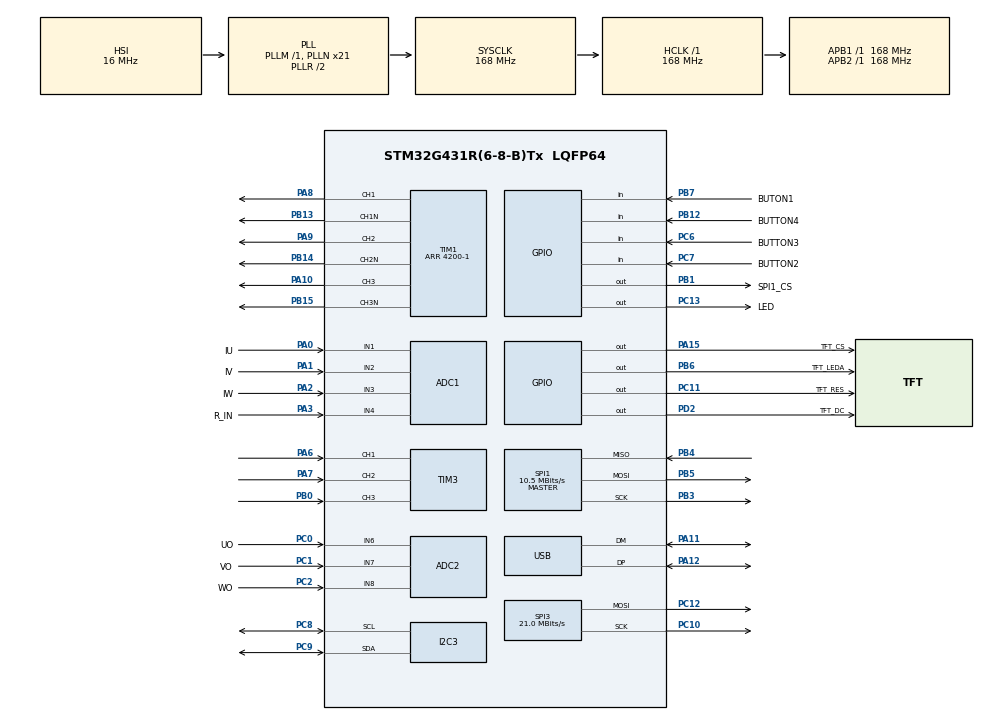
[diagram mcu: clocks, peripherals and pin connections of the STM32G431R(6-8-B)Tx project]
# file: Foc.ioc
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ADC1.Channel-0\#ChannelRegularConversion=ADC_CHANNEL_1
ADC1.ContinuousConvMode=ENABLE
ADC1.EOCSelection=ADC_EOC_SEQ_CONV
ADC1.EnableInjectedConversion=ENABLE
ADC1.EnableInjectedOversampling=DISABLE
ADC1.ExternalTrigInjecConv=ADC_EXTERNALTRIGINJEC_T1_CC4
ADC1.InjNumberOfConversion=4
ADC1.InjectedChannel-1\#ChannelInjectedConversion=ADC_CHANNEL_2
ADC1.InjectedChannel-2\#ChannelInjectedConversion=ADC_CHANNEL_3
ADC1.InjectedChannel-3\#ChannelInjectedConversion=ADC_CHANNEL_1
ADC1.InjectedChannel-4\#ChannelInjectedConversion=ADC_CHANNEL_4
ADC1.InjectedOffsetNumber-1\#ChannelInjectedConversion=ADC_OFFSET_NONE
ADC1.InjectedOffsetNumber-2\#ChannelInjectedConversion=ADC_OFFSET_NONE
ADC1.InjectedOffsetNumber-3\#ChannelInjectedConversion=ADC_OFFSET_NONE
ADC1.InjectedOffsetNumber-4\#ChannelInjectedConversion=ADC_OFFSET_NONE
ADC1.InjectedRank-1\#ChannelInjectedConversion=1
ADC1.InjectedRank-2\#ChannelInjectedConversion=2
ADC1.InjectedRank-3\#ChannelInjectedConversion=3
ADC1.InjectedRank-4\#ChannelInjectedConversion=4
ADC1.InjectedSamplingTime-1\#ChannelInjectedConversion=ADC_SAMPLETIME_2CYCLES_5
ADC1.InjectedSamplingTime-2\#ChannelInjectedConversion=ADC_SAMPLETIME_2CYCLES_5
ADC1.InjectedSamplingTime-3\#ChannelInjectedConversion=ADC_SAMPLETIME_2CYCLES_5
ADC1.InjectedSamplingTime-4\#ChannelInjectedConversion=ADC_SAMPLETIME_2CYCLES_5
ADC1.NbrOfConversionFlag=1
ADC1.OffsetNumber-0\#ChannelRegularConversion=ADC_OFFSET_NONE
ADC1.Rank-0\#ChannelRegularConversion=1
ADC1.Rank1_Channel=ADC_CHANNEL_2
ADC1.Rank2_Channel=ADC_CHANNEL_3
ADC1.Rank3_Channel=ADC_CHANNEL_1
ADC1.Rank4_Channel=ADC_CHANNEL_4
ADC1.SamplingTime-0\#ChannelRegularConversion=ADC_SAMPLETIME_2CYCLES_5
ADC1.master=1
ADC2.Channel-10\#ChannelRegularConversion=ADC_CHANNEL_6
ADC2.Channel-11\#ChannelRegularConversion=ADC_CHANNEL_7
ADC2.Channel-12\#ChannelRegularConversion=ADC_CHANNEL_8
ADC2.ContinuousConvMode=ENABLE
ADC2.EOCSelection=ADC_EOC_SEQ_CONV
ADC2.EnableRegularConversion=ENABLE
ADC2.NbrOfConversion=3
ADC2.NbrOfConversionFlag=1
ADC2.OffsetNumber-10\#ChannelRegularConversion=ADC_OFFSET_NONE
ADC2.OffsetNumber-11\#ChannelRegularConversion=ADC_OFFSET_NONE
ADC2.OffsetNumber-12\#ChannelRegularConversion=ADC_OFFSET_NONE
ADC2.Rank-10\#ChannelRegularConversion=1
ADC2.Rank-11\#ChannelRegularConversion=2
ADC2.Rank-12\#ChannelRegularConversion=3
ADC2.SamplingTime-10\#ChannelRegularConversion=ADC_SAMPLETIME_6CYCLES_5
ADC2.SamplingTime-11\#ChannelRegularConversion=ADC_SAMPLETIME_6CYCLES_5
ADC2.SamplingTime-12\#ChannelRegularConversion=ADC_SAMPLETIME_6CYCLES_5
Dma.ADC1.1.Direction=DMA_PERIPH_TO_MEMORY
Dma.ADC1.1.EventEnable=DISABLE
Dma.ADC1.1.Instance=DMA1_Channel2
Dma.ADC1.1.MemDataAlignment=DMA_MDATAALIGN_HALFWORD
Dma.ADC1.1.MemInc=DMA_MINC_ENABLE
Dma.ADC1.1.Mode=DMA_CIRCULAR
Dma.ADC1.1.PeriphDataAlignment=DMA_PDATAALIGN_HALFWORD
Dma.ADC1.1.PeriphInc=DMA_PINC_DISABLE
Dma.ADC1.1.Polarity=HAL_DMAMUX_REQ_GEN_RISING
Dma.ADC1.1.Priority=DMA_PRIORITY_LOW
Dma.ADC1.1.RequestNumber=1
Dma.ADC1.1.SignalID=NONE
Dma.ADC1.1.SyncEnable=DISABLE
Dma.ADC1.1.SyncPolarity=HAL_DMAMUX_SYNC_NO_EVENT
Dma.ADC1.1.SyncRequestNumber=1
Dma.ADC1.1.SyncSignalID=NONE
Dma.Request0=SPI3_TX
Dma.Request1=ADC1
Dma.Request2=SPI1_TX
Dma.SPI1_TX.2.Direction=DMA_MEMORY_TO_PERIPH
Dma.SPI1_TX.2.EventEnable=DISABLE
Dma.SPI1_TX.2.Instance=DMA1_Channel3
Dma.SPI1_TX.2.MemDataAlignment=DMA_MDATAALIGN_HALFWORD
Dma.SPI1_TX.2.MemInc=DMA_MINC_ENABLE
Dma.SPI1_TX.2.Mode=DMA_NORMAL
Dma.SPI1_TX.2.PeriphDataAlignment=DMA_PDATAALIGN_HALFWORD
Dma.SPI1_TX.2.PeriphInc=DMA_PINC_DISABLE
Dma.SPI1_TX.2.Polarity=HAL_DMAMUX_REQ_GEN_RISING
Dma.SPI1_TX.2.Priority=DMA_PRIORITY_LOW
Dma.SPI1_TX.2.RequestNumber=1
Dma.SPI1_TX.2.SignalID=NONE
Dma.SPI1_TX.2.SyncEnable=DISABLE
Dma.SPI1_TX.2.SyncPolarity=HAL_DMAMUX_SYNC_NO_EVENT
Dma.SPI1_TX.2.SyncRequestNumber=1
Dma.SPI1_TX.2.SyncSignalID=NONE
Dma.SPI3_TX.0.Direction=DMA_MEMORY_TO_PERIPH
Dma.SPI3_TX.0.EventEnable=DISABLE
Dma.SPI3_TX.0.Instance=DMA1_Channel1
Dma.SPI3_TX.0.MemDataAlignment=DMA_MDATAALIGN_BYTE
Dma.SPI3_TX.0.MemInc=DMA_MINC_ENABLE
Dma.SPI3_TX.0.Mode=DMA_NORMAL
Dma.SPI3_TX.0.PeriphDataAlignment=DMA_PDATAALIGN_BYTE
Dma.SPI3_TX.0.PeriphInc=DMA_PINC_DISABLE
Dma.SPI3_TX.0.Polarity=HAL_DMAMUX_REQ_GEN_RISING
Dma.SPI3_TX.0.Priority=DMA_PRIORITY_LOW
Dma.SPI3_TX.0.RequestNumber=1
Dma.SPI3_TX.0.SignalID=NONE
Dma.SPI3_TX.0.SyncEnable=DISABLE
Dma.SPI3_TX.0.SyncPolarity=HAL_DMAMUX_SYNC_NO_EVENT
Dma.SPI3_TX.0.SyncRequestNumber=1
Dma.SPI3_TX.0.SyncSignalID=NONE
I2C3.Timing=0x60505F8C
Mcu.Family=STM32G4
Mcu.Name=STM32G431R(6-8-B)Tx
Mcu.Package=LQFP64
NVIC.ADC1_2_IRQn=true\:0\:0\:false\:false\:true\:true\:true\:true
NVIC.DMA1_Channel1_IRQn=true\:0\:0\:false\:false\:true\:false\:true\:true
NVIC.DMA1_Channel2_IRQn=true\:0\:0\:false\:false\:true\:false\:true\:true
NVIC.DMA1_Channel3_IRQn=true\:0\:0\:false\:false\:true\:false\:true\:true
NVIC.PriorityGroup=NVIC_PRIORITYGROUP_4
NVIC.TIM3_IRQn=true\:1\:0\:true\:false\:true\:true\:true\:true
NVIC.TIM4_IRQn=true\:2\:0\:true\:false\:true\:true\:true\:true
NVIC.USB_LP_IRQn=true\:0\:0\:false\:false\:true\:false\:true\:true
PA0.GPIO_Label=IU
PA0.Mode=IN1-Single-Ended
PA0.Signal=ADC1_IN1
PA1.GPIO_Label=IV
PA1.Mode=IN2-Single-Ended
PA1.Signal=ADC1_IN2
PA10.Signal=S_TIM1_CH3
PA11.Mode=Device
PA11.Signal=USB_DM
PA12.Mode=Device
PA12.Signal=USB_DP
PA13.Mode=Serial_Wire
PA13.Signal=SYS_JTMS-SWDIO
PA14.Mode=Serial_Wire
PA14.Signal=SYS_JTCK-SWCLK
PA15.GPIO_Label=TFT_CS
PA15.GPIO_Speed=GPIO_SPEED_FREQ_HIGH
PA15.Signal=GPIO_Output
PA2.GPIO_Label=IW
PA2.Mode=IN3-Single-Ended
PA2.Signal=ADC1_IN3
PA3.GPIO_Label=R_IN
PA3.Mode=IN4-Single-Ended
PA3.Signal=ADC1_IN4
PA5.GPIO_Label=IBUS
PA5.Signal=ADC2_IN13
PA6.Signal=S_TIM3_CH1
PA7.Signal=S_TIM3_CH2
PA8.Signal=S_TIM1_CH1
PA9.Signal=S_TIM1_CH2
PB0.Signal=S_TIM3_CH3
PB1.GPIO_Label=SPI1_CS
PB1.GPIO_Speed=GPIO_SPEED_FREQ_HIGH
PB1.Signal=GPIO_Output
PB12.GPIO_Label=BUTTON4
PB12.Signal=GPIO_Input
PB13.Mode=PWM Generation1 CH1 CH1N
PB13.Signal=TIM1_CH1N
PB14.Mode=PWM Generation2 CH2 CH2N
PB14.Signal=TIM1_CH2N
PB15.Mode=PWM Generation3 CH3 CH3N
PB15.Signal=TIM1_CH3N
PB2.Signal=ADC2_IN12
PB3.Mode=Full_Duplex_Master
PB3.Signal=SPI1_SCK
PB4.Mode=Full_Duplex_Master
PB4.Signal=SPI1_MISO
PB5.Mode=Full_Duplex_Master
PB5.Signal=SPI1_MOSI
PB6.GPIO_FM6=SYSCFG_FASTMODEPLUS_PB6
PB6.GPIO_Label=TFT_LEDA
PB6.GPIO_Speed=GPIO_SPEED_FREQ_HIGH
PB6.Signal=GPIO_Output
PB7.GPIO_Label=BUTON1
PB7.Signal=GPIO_Input
PC0.GPIO_Label=UO
PC0.Mode=IN6-Single-Ended
PC0.Signal=ADC2_IN6
PC1.GPIO_Label=VO
PC1.Mode=IN7-Single-Ended
PC1.Signal=ADC2_IN7
PC10.Mode=TX_Only_Simplex_Unidirect_Master
PC10.Signal=SPI3_SCK
PC11.GPIO_Label=TFT_RES
PC11.GPIO_Speed=GPIO_SPEED_FREQ_HIGH
PC11.Signal=GPIO_Output
PC12.Mode=TX_Only_Simplex_Unidirect_Master
PC12.Signal=SPI3_MOSI
PC13.GPIO_Label=LED
PC13.Signal=GPIO_Output
PC2.GPIO_Label=WO
PC2.Mode=IN8-Single-Ended
PC2.Signal=ADC2_IN8
PC3.GPIO_Label=NTC1
PC3.Signal=ADC2_IN9
PC4.Signal=ADC2_IN5
PC5.Signal=ADC2_IN11
PC6.GPIO_Label=BUTTON3
PC6.Signal=GPIO_Input
PC7.GPIO_Label=BUTTON2
PC7.Signal=GPIO_Input
PC8.Mode=I2C
PC8.Signal=I2C3_SCL
PC9.Mode=I2C
PC9.Signal=I2C3_SDA
PD2.GPIO_Label=TFT_DC
PD2.GPIO_Speed=GPIO_SPEED_FREQ_HIGH
PD2.Signal=GPIO_Output
PF0-OSC_IN.Mode=HSE-External-Oscillator
PF0-OSC_IN.Signal=RCC_OSC_IN
PF1-OSC_OUT.Mode=HSE-External-Oscillator
PF1-OSC_OUT.Signal=RCC_OSC_OUT
ProjectManager.HeapSize=0x200
ProjectManager.StackSize=0x400
ProjectManager.TargetToolchain=MDK-ARM V5.32
RCC.ADC12Freq_Value=168000000
RCC.AHBFreq_Value=168000000
RCC.APB1Freq_Value=168000000
RCC.APB1TimFreq_Value=168000000
RCC.APB2Freq_Value=168000000
RCC.APB2TimFreq_Value=168000000
RCC.CK48CLockSelection=RCC_USBCLKSOURCE_HSI48
RCC.CortexFreq_Value=168000000
RCC.EXTERNAL_CLOCK_VALUE=12288000
RCC.HCLKFreq_Value=168000000
RCC.HSE_VALUE=8000000
RCC.HSI48_VALUE=48000000
RCC.HSI_VALUE=16000000
RCC.LSE_VALUE=32768
RCC.PLLN=21
RCC.SYSCLKFreq_VALUE=168000000
RCC.SYSCLKSource=RCC_SYSCLKSOURCE_PLLCLK
RCC.USBFreq_Value=48000000
RCC.VCOOutputFreq_Value=336000000
SH.S_TIM1_CH1.0=TIM1_CH1,PWM Generation1 CH1 CH1N
SH.S_TIM1_CH2.0=TIM1_CH2,PWM Generation2 CH2 CH2N
SH.S_TIM1_CH3.0=TIM1_CH3,PWM Generation3 CH3 CH3N
SH.S_TIM3_CH1.0=TIM3_CH1,Encoder_Interface
SH.S_TIM3_CH2.0=TIM3_CH2,Encoder_Interface
SH.S_TIM3_CH3.0=TIM3_CH3,Input_Capture3_from_TI3
SPI1.BaudRatePrescaler=SPI_BAUDRATEPRESCALER_16
SPI1.CalculateBaudRate=10.5 MBits/s
SPI1.DataSize=SPI_DATASIZE_16BIT
SPI1.Direction=SPI_DIRECTION_2LINES
SPI1.Mode=SPI_MODE_MASTER
SPI1.VirtualType=VM_MASTER
SPI3.BaudRatePrescaler=SPI_BAUDRATEPRESCALER_8
SPI3.CalculateBaudRate=21.0 MBits/s
SPI3.DataSize=SPI_DATASIZE_8BIT
SPI3.Direction=SPI_DIRECTION_2LINES
SPI3.Mode=SPI_MODE_MASTER
SPI3.VirtualType=VM_MASTER
STMicroelectronics.X-CUBE-ALGOBUILD.1.4.0.LibraryCcDSPOoLibraryJjDSPOoLibrary=true
TIM1.AutoReloadPreload=TIM_AUTORELOAD_PRELOAD_ENABLE
TIM1.Channel-PWM\ Generation1\ CH1\ CH1N=TIM_CHANNEL_1
TIM1.Channel-PWM\ Generation2\ CH2\ CH2N=TIM_CHANNEL_2
TIM1.Channel-PWM\ Generation3\ CH3\ CH3N=TIM_CHANNEL_3
TIM1.Channel-PWM\ Generation4\ No\ Output=TIM_CHANNEL_4
TIM1.CounterMode=TIM_COUNTERMODE_CENTERALIGNED1
TIM1.DeadTime=10
TIM1.OCMode_PWM-PWM\ Generation4\ No\ Output=TIM_OCMODE_PWM2
TIM1.PeriodNoDither=4200-1
TIM1.PulseNoDither_4=4200-5
TIM1.TIM_MasterOutputTrigger=TIM_TRGO_OC4REF
TIM3.Channel-Input_Capture3_from_TI3=TIM_CHANNEL_3
TIM3.EncoderMode=TIM_ENCODERMODE_TI12
TIM4.AutoReloadPreload=TIM_AUTORELOAD_PRELOAD_ENABLE
TIM4.PeriodNoDither=1000-1
TIM4.Prescaler=168-1
USB_DEVICE.CLASS_NAME_FS=CDC
USB_DEVICE.VirtualMode=Cdc
USB_DEVICE.VirtualModeFS=Cdc_FS
VP_CORDIC_VS_CORDIC.Mode=CORDIC_Activate
VP_STMicroelectronics.X-CUBE-ALGOBUILD_VS_DSPOoLibraryJjLibrary_1.4.0_1.4.0.Mode=DSPOoLibraryJjLibrary
VP_SYS_VS_DBSignals.Mode=DisableDeadBatterySignals
VP_TIM1_VS_ClockSourceINT.Mode=Internal
VP_TIM1_VS_no_output4.Mode=PWM Generation4 No Output
VP_TIM4_VS_ClockSourceINT.Mode=Internal
VP_USB_DEVICE_VS_USB_DEVICE_CDC_FS.Mode=CDC_FS
board=custom

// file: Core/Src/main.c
/* USER CODE BEGIN Header */
/**
  ******************************************************************************
  * @file           : main.c
  * @brief          : Main program body
  ******************************************************************************
  * @attention
  *
  * Copyright (c) 2025 STMicroelectronics.
  * All rights reserved.
  *
  * This software is licensed under terms that can be found in the LICENSE file
  * in the root directory of this software component.
  * If no LICENSE file comes with this software, it is provided AS-IS.
  *
  ******************************************************************************
  */
/* USER CODE END Header */
#include "main.h"
#include "adc.h"
#include "cordic.h"
#include "dma.h"
#include "i2c.h"
#include "spi.h"
#include "tim.h"
#include "usb_device.h"
#include "gpio.h"

/* USER CODE BEGIN Includes */
#include "Task.h"
/* USER CODE END Includes */

void SystemClock_Config(void);

int main(void)
{

  /* MCU Configuration--------------------------------------------------------*/

  /* Reset of all peripherals, Initializes the Flash interface and the Systick. */
  HAL_Init();

  /* Configure the system clock */
  SystemClock_Config();

  /* Initialize all configured peripherals */
  MX_GPIO_Init();
  MX_DMA_Init();
  MX_ADC1_Init();
  MX_ADC2_Init();
  MX_TIM1_Init();
  MX_SPI1_Init();
  MX_SPI3_Init();
  MX_USB_Device_Init();
  MX_I2C3_Init();
  MX_TIM4_Init();
  MX_CORDIC_Init();
  MX_TIM3_Init();
  /* USER CODE BEGIN 2 */
  Sysinit();
  /* USER CODE END 2 */

  /* Infinite loop */
  /* USER CODE BEGIN WHILE */
  while (1)
  {
    SysRun();
    /* USER CODE END WHILE */

  }
}

void SystemClock_Config(void)
{
  RCC_OscInitTypeDef RCC_OscInitStruct = {0};
  RCC_ClkInitTypeDef RCC_ClkInitStruct = {0};

  /** Configure the main internal regulator output voltage
  */
  HAL_PWREx_ControlVoltageScaling(PWR_REGULATOR_VOLTAGE_SCALE1_BOOST);

  /** Initializes the RCC Oscillators according to the specified parameters
  * in the RCC_OscInitTypeDef structure.
  */
  RCC_OscInitStruct.OscillatorType = RCC_OSCILLATORTYPE_HSI|RCC_OSCILLATORTYPE_HSI48;
  RCC_OscInitStruct.HSIState = RCC_HSI_ON;
  RCC_OscInitStruct.HSICalibrationValue = RCC_HSICALIBRATION_DEFAULT;
  RCC_OscInitStruct.HSI48State = RCC_HSI48_ON;
  RCC_OscInitStruct.PLL.PLLState = RCC_PLL_ON;
  RCC_OscInitStruct.PLL.PLLSource = RCC_PLLSOURCE_HSI;
  RCC_OscInitStruct.PLL.PLLM = RCC_PLLM_DIV1;
  RCC_OscInitStruct.PLL.PLLN = 21;
  RCC_OscInitStruct.PLL.PLLP = RCC_PLLP_DIV2;
  RCC_OscInitStruct.PLL.PLLQ = RCC_PLLQ_DIV2;
  RCC_OscInitStruct.PLL.PLLR = RCC_PLLR_DIV2;
  if (HAL_RCC_OscConfig(&RCC_OscInitStruct) != HAL_OK)
  {
    Error_Handler();
  }

  /** Initializes the CPU, AHB and APB buses clocks
  */
  RCC_ClkInitStruct.ClockType = RCC_CLOCKTYPE_HCLK|RCC_CLOCKTYPE_SYSCLK
                              |RCC_CLOCKTYPE_PCLK1|RCC_CLOCKTYPE_PCLK2;
  RCC_ClkInitStruct.SYSCLKSource = RCC_SYSCLKSOURCE_PLLCLK;
  RCC_ClkInitStruct.AHBCLKDivider = RCC_SYSCLK_DIV1;
  RCC_ClkInitStruct.APB1CLKDivider = RCC_HCLK_DIV1;
  RCC_ClkInitStruct.APB2CLKDivider = RCC_HCLK_DIV1;

  if (HAL_RCC_ClockConfig(&RCC_ClkInitStruct, FLASH_LATENCY_4) != HAL_OK)
  {
    Error_Handler();
  }
}

void Error_Handler(void)
{
  __disable_irq();
  while (1)
  {
  }
}
